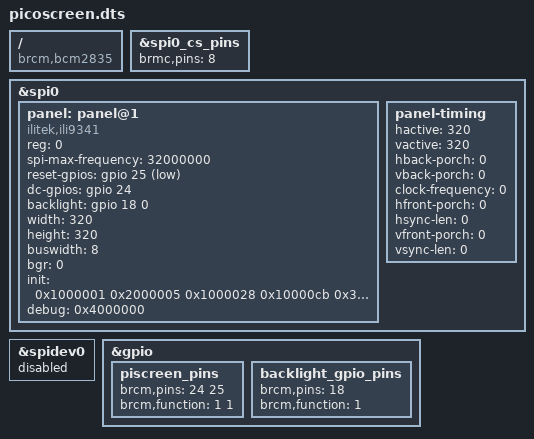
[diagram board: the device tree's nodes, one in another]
/dts-v1/;
/plugin/;

//#include <dt-bindings/gpio/gpio.h>

/ {
	compatible = "brcm,bcm2835";

	// Enable the SPI controller
	fragment@0 {
		target = <&spi0_cs_pins>;
		frag0: __overlay__ {
			brmc,pins=<8>;
		};
	};

	// Enable the SPI controller
	fragment@1 {
		target = <&spi0>;
		frag1: __overlay__ {
                //        cs-gpios = <&gpio 8 1>
			status = "okay";
		};
	};

	// Enabling the SPI controller also enables spidev on cs0, so we have disable it
	fragment@2 {
		target = <&spidev0>;
		__overlay__ {
			status = "disabled";
		};
	};
   
        fragment@3 {
                target = <&spi0_pins>;
		__dormant__ {
                      brcm,pins = <10 11>;
               };
        };
        fragment@4 {
                target = <&gpio>;
                __overlay__ {
                        piscreen_pins: piscreen_pins {
                                brcm,pins = <24 25>;
                                brcm,function = <1 1>; /* out out */
                        };
                };
        };

	fragment@5 {
		target = <&spi0>;
		__overlay__ {
			/* needed to avoid dtc warning */
			#address-cells = <1>;
			#size-cells = <0>;

			panel: panel@1{
				// MIPI DBI compatible driver
				// This driver is used because it can ignore an illegal rotate value
				// and doesn't have a set_gamma() function.
				compatible = "ilitek,ili9341";
				reg = <0>; // Chip Select 0

				spi-max-frequency = <32000000>; // 32MHz

				reset-gpios = <&gpio 25 1>; // reset is active low hence the 1
				dc-gpios = <&gpio 24 0>;
				backlight = <&gpio 18 0>;

				width = <320>;
				height = <320>;
				buswidth = <8>; // Most controllers use this value
                                bgr = <0>;
				// This is a hack to prevent fb_s6d02a1.c:set_var() from issuing
				// command 0x36 after the init sequence has been applied and thus
				// changing the config.
				//rotate = <180>;


				// see drivers/staging/fbtft/fb_ili9341.c:init_display() for how this looks in the driver
				// Command 0x36 is taken from the fb_ili9341.c:set_var() function.
				init = <0x1000001
					0x2000005
					0x1000028
					0x10000cb 0x39 0x2c 0x00 0x34 0x02
					0x10000cf 0x00 0xc1 0x30
					0x10000ed 0x64 0x03 0x12 0x81
					0x10000e8 0x85 0x00 0x78
					0x10000ea 0x00 0x00
                                        0x10000f7 0x20
					0x10000c0 0x23
					0x10000c1 0x10
					0x10000c5 0x3e 0x28
                                        0x10000c7 0x86
					0x1000036 0x00
					0x1000021
					0x100003a 0x55
					0x10000b1 0x00 0x11
                                        0x10000b6 0x08 0x82 0x27
                                        0x10000f2 0x02
                                        0x1000026 0x01
                                        0x10000b4 0x02
                                        0x10000e0 0x0f 0x31 0x2b 0x0c 0x0e 0x08 0x4e 0xf1 0x37 0x07 0x10 0x03 0x0e 0x09 0x00
                                        0x10000e1 0x00 0x0e 0x14 0x03 0x11 0x07 0x31 0xc1 0x48 0x08 0x0f 0x0c 0x31 0x36 0x0f
					0x1000011
					0x2000064
					0x1000029
					0x2000020>;

				debug = <0x4000000>; // print init commands to the kernel log
			};


                                panel-timing {
                                        hactive = <320>;
                                        vactive = <320>;
                                        hback-porch = <0>;
                                        vback-porch = <0>;
                                        clock-frequency = <0>;
                                        hfront-porch = <0>;
                                        hsync-len = <0>;
                                        vfront-porch = <0>;
                                        vsync-len = <0>;
                                };
		};
	};


        fragment@10 {
                target = <&gpio>;
                __overlay__ {
                        backlight_gpio_pins: backlight_gpio_pins {
                                brcm,pins = <18>;
                                brcm,function = <1>; /* out */
                        };
                };
        };


        __overrides__ {
                compatible    = <&panel>, "compatible";

                //cs0_pin           = <&frag0>,"brcm,pins:0",
                //                                <&frag1>,"cs-gpios:4";
                no_miso           = <0>,"=3";   
        
                speed =         <&panel>,"spi-max-frequency:0";
                cpha          = <&panel>, "spi-cpha?";
                cpol          = <&panel>, "spi-cpol?";
                write-only    = <&panel>, "write-only?";                
                rotation =        <&panel>,"rotation:0";
                fps =           <&panel>,"fps:0";
                debug =         <&panel>,"debug:0";
                drm =           <&panel>,"compatible=ilitek,ili9341",
                                <&panel>,"reset-gpios:25=1";
        };
};

